# jbr_MDR1901VC1T register map
Registers from a debugger description file.
Registers are 32-bit, access not given, no defined reset value unless marked. A register's access mark holds for its fields unless they carry their own. Addresses are absolute; registers are grouped by the start of their names; lines under a group give offsets from that group; [hi:lo] are bit positions; {n}, {i} and the like mark numbered series; 'fields as' and 'values as' point back to an identical list; <NAME> marks a mode.

## USB
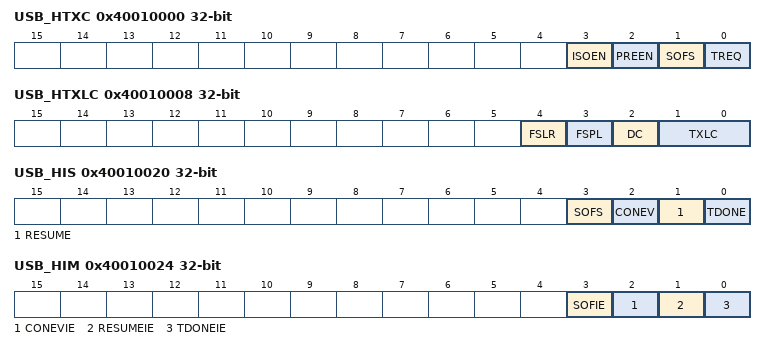
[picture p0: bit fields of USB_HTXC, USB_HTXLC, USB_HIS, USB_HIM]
0x40010000 USB_HTXC
  [3] ISOEN, [2] PREEN, [1] SOFS, [0] TREQ
0x40010004 USB_HTXT
  [1:0] TTYPE
0x40010008 USB_HTXLC
  [4] FSLR, [3] FSPL, [2] DC, [1:0] TXLC
0x4001000C USB_HTXSE
  [0] SOFEN
0x40010010 USB_HTXA
  [6:0] DEVADDR
0x40010014 USB_HTXE
  [3:0] EPADDR
0x40010018 USB_HFN_L
  [10:0] FNUM
0x4001001C USB_HFN_H
  [10:0] FNUM
0x40010020 USB_HIS
  [3] SOFS, [2] CONEV, [1] RESUME, [0] TDONE
0x40010024 USB_HIM
  [3] SOFIE, [2] CONEVIE, [1] RESUMEIE, [0] TDONEIE
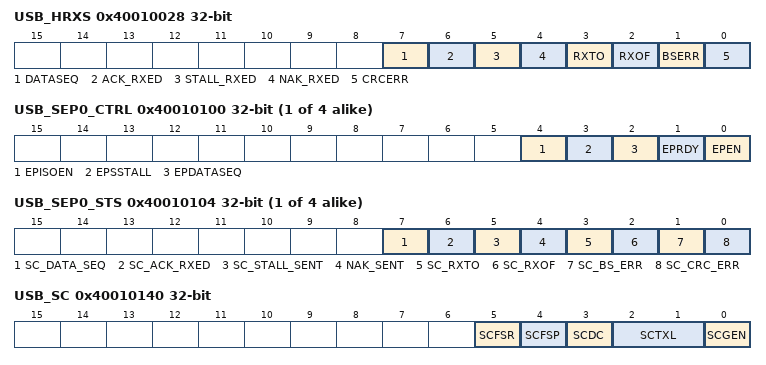
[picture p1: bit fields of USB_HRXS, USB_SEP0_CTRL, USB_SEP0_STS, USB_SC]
0x40010028 USB_HRXS
  [7] DATASEQ, [6] ACK_RXED, [5] STALL_RXED, [4] NAK_RXED, [3] RXTO, [2] RXOF, [1] BSERR, [0] CRCERR
0x4001002C USB_HRXP
  [3:0] RPID
0x40010030 USB_HRXA
  [6:0] RADDR
0x40010034 USB_HRXE
  [3:0] RXENDP
0x40010038 USB_HRXCS
  [1:0] RXLS
0x4001003C USB_HSTM
  [7:0] HSTM
0x40010080 USB_HRXFD
  [7:0] RX_FIFO_DATA
0x40010088 USB_HRXDC_L
  [15:0] FIFO_DATA_COUNT
0x4001008C USB_HRXDC_H
  [15:0] FIFO_DATA_COUNT
0x40010090 USB_HRXFC
  [0] FIFO_FORCE_EMPTY
0x400100C0 USB_HTXFD
  [7:0] TX_FIFO_DATA
0x400100D0 USB_HTXFC
  [0] FIFO_FORCE_EMPTY
{0x40010100+0x10*i} USB_SEP{i}_CTRL (i=0..3)
  [4] EPISOEN, [3] EPSSTALL, [2] EPDATASEQ, [1] EPRDY, [0] EPEN
{0x40010104+0x10*i} USB_SEP{i}_STS (i=0..3)
  [7] SC_DATA_SEQ, [6] SC_ACK_RXED, [5] SC_STALL_SENT, [4] NAK_SENT, [3] SC_RXTO, [2] SC_RXOF, [1] SC_BS_ERR, [0] SC_CRC_ERR
{0x40010108+0x10*i} USB_SEP{i}_TS (i=0..3)
  [1:0] SCTTYPE
{0x4001010C+0x10*i} USB_SEP{i}_NTS (i=0..3)
  [1:0] NTTYPE
0x40010140 USB_SC
  [5] SCFSR, [4] SCFSP, [3] SCDC, [2:1] SCTXL, [0] SCGEN
0x40010144 USB_SLS
  [1:0] SCRXLS
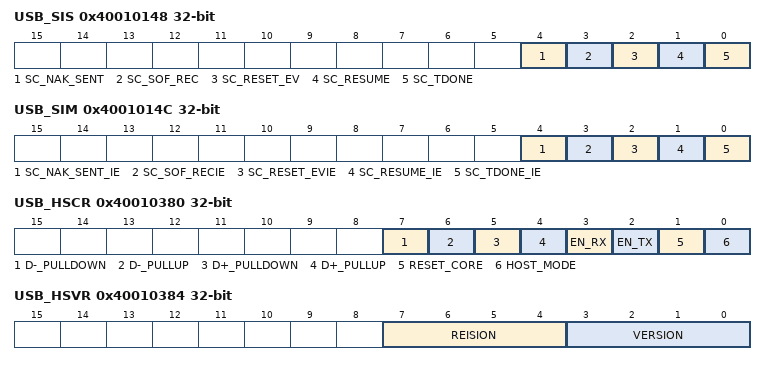
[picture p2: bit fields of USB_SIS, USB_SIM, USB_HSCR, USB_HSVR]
0x40010148 USB_SIS
  [4] SC_NAK_SENT, [3] SC_SOF_REC, [2] SC_RESET_EV, [1] SC_RESUME, [0] SC_TDONE
0x4001014C USB_SIM
  [4] SC_NAK_SENT_IE, [3] SC_SOF_RECIE, [2] SC_RESET_EVIE, [1] SC_RESUME_IE, [0] SC_TDONE_IE
0x40010150 USB_SA
  [6:0] SDEVADDR
0x40010154 USB_SFN_L
  [10:0] FRAME_NUM
0x40010158 USB_SFN_H
  [10:0] FRAME_NUM
{0x40010180+0x80*i} USB_SEP{i}_RXFD (i=0..3)
  [7:0] RX_FIFO_DATA
{0x40010188+0x80*i} USB_SEP{i}_RXFDC_L (i=0..3)
  [15:0] FIFO_DATA_COUNT
{0x4001018C+0x80*i} USB_SEP{i}_RXFDC_H (i=0..3)
  [15:0] FIFO_DATA_COUNT
{0x40010190+0x80*i} USB_SEP{i}_RXFC (i=0..3)
  [0] FIFO_FORCE_EMPTY
{0x400101C0+0x80*i} USB_SEP{i}_TXFD (i=0..3)
  [7:0] TX_FIFO_DATA
{0x400101D0+0x80*i} USB_SEP{i}_TXFDC (i=0..3)
  [0] FIFO_FORCE_EMPTY
0x40010380 USB_HSCR
  [7] D-_PULLDOWN, [6] D-_PULLUP, [5] D+_PULLDOWN, [4] D+_PULLUP, [3] EN_RX, [2] EN_TX, [1] RESET_CORE, [0] HOST_MODE
0x40010384 USB_HSVR
  [7:4] REISION, [3:0] VERSION

## EEPROM
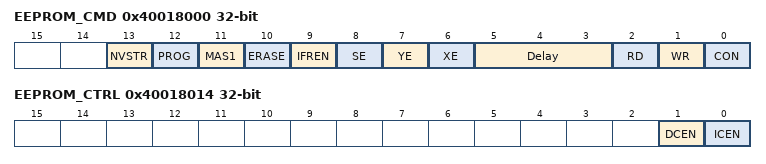
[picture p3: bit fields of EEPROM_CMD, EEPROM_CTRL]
0x40018000 EEPROM_CMD
  [13] NVSTR, [12] PROG, [11] MAS1, [10] ERASE, [9] IFREN, [8] SE, [7] YE, [6] XE, [5:3] Delay, [2] RD, [1] WR, [0] CON
0x40018004 EEPROM_ADR
0x40018008 EEPROM_DI
  [31:0] DATA
0x4001800C EEPROM_DO
  [31:0] DATA
0x40018010 EEPROM_KEY
0x40018014 EEPROM_CTRL
  [1] DCEN, [0] ICEN

## RST
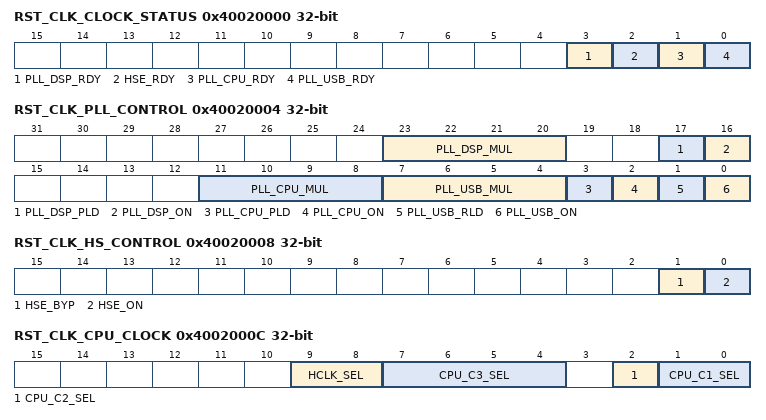
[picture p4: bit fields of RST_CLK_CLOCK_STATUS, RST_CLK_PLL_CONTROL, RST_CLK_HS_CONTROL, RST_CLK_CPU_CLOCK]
0x40020000 RST_CLK_CLOCK_STATUS
  [3] PLL_DSP_RDY, [2] HSE_RDY, [1] PLL_CPU_RDY, [0] PLL_USB_RDY
0x40020004 RST_CLK_PLL_CONTROL
  [23:20] PLL_DSP_MUL, [17] PLL_DSP_PLD, [16] PLL_DSP_ON, [11:8] PLL_CPU_MUL, [7:4] PLL_USB_MUL, [3] PLL_CPU_PLD, [2] PLL_CPU_ON, [1] PLL_USB_RLD, [0] PLL_USB_ON
0x40020008 RST_CLK_HS_CONTROL
  [1] HSE_BYP, [0] HSE_ON
0x4002000C RST_CLK_CPU_CLOCK
  [9:8] HCLK_SEL, [7:4] CPU_C3_SEL, [2] CPU_C2_SEL, [1:0] CPU_C1_SEL
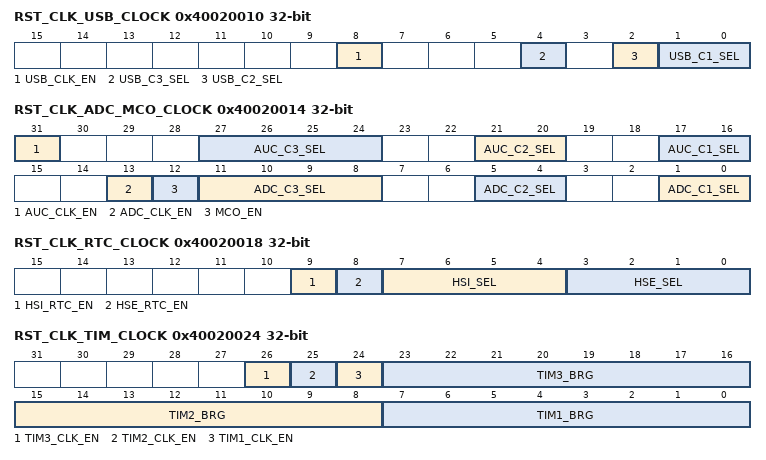
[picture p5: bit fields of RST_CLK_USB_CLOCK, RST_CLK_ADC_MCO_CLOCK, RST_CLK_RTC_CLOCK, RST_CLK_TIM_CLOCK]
0x40020010 RST_CLK_USB_CLOCK
  [8] USB_CLK_EN, [4] USB_C3_SEL, [2] USB_C2_SEL, [1:0] USB_C1_SEL
0x40020014 RST_CLK_ADC_MCO_CLOCK
  [31] AUC_CLK_EN, [27:24] AUC_C3_SEL, [21:20] AUC_C2_SEL, [17:16] AUC_C1_SEL, [13] ADC_CLK_EN, [12] MCO_EN, [11:8] ADC_C3_SEL, [5:4] ADC_C2_SEL, [1:0] ADC_C1_SEL
0x40020018 RST_CLK_RTC_CLOCK
  [9] HSI_RTC_EN, [8] HSE_RTC_EN, [7:4] HSI_SEL, [3:0] HSE_SEL
0x4002001C RST_CLK_PER_CLOCK
  [31:0] PCLK_EN
0x40020024 RST_CLK_TIM_CLOCK
  [26] TIM3_CLK_EN, [25] TIM2_CLK_EN, [24] TIM1_CLK_EN, [23:16] TIM3_BRG, [15:8] TIM2_BRG, [7:0] TIM1_BRG
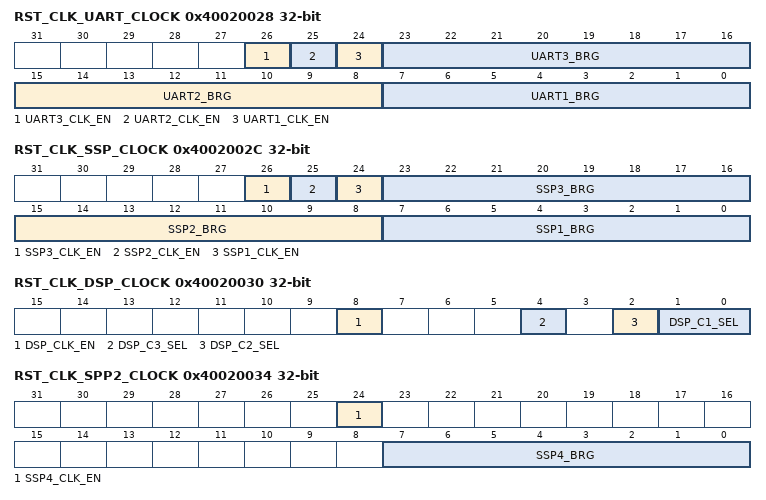
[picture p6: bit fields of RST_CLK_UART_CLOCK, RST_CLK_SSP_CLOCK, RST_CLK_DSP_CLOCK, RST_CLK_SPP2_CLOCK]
0x40020028 RST_CLK_UART_CLOCK
  [26] UART3_CLK_EN, [25] UART2_CLK_EN, [24] UART1_CLK_EN, [23:16] UART3_BRG, [15:8] UART2_BRG, [7:0] UART1_BRG
0x4002002C RST_CLK_SSP_CLOCK
  [26] SSP3_CLK_EN, [25] SSP2_CLK_EN, [24] SSP1_CLK_EN, [23:16] SSP3_BRG, [15:8] SSP2_BRG, [7:0] SSP1_BRG
0x40020030 RST_CLK_DSP_CLOCK
  [8] DSP_CLK_EN, [4] DSP_C3_SEL, [2] DSP_C2_SEL, [1:0] DSP_C1_SEL
0x40020034 RST_CLK_SPP2_CLOCK
  [24] SSP4_CLK_EN, [7:0] SSP4_BRG
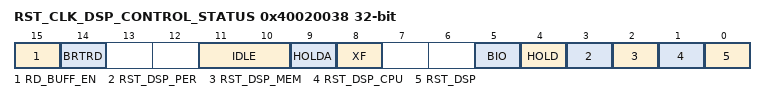
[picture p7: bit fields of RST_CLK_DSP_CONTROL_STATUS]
0x40020038 RST_CLK_DSP_CONTROL_STATUS
  [15] RD_BUFF_EN, [14] BRTRD, [11:10] IDLE, [9] HOLDA, [8] XF, [5] BIO, [4] HOLD, [3] RST_DSP_PER, [2] RST_DSP_MEM, [1] RST_DSP_CPU, [0] RST_DSP
